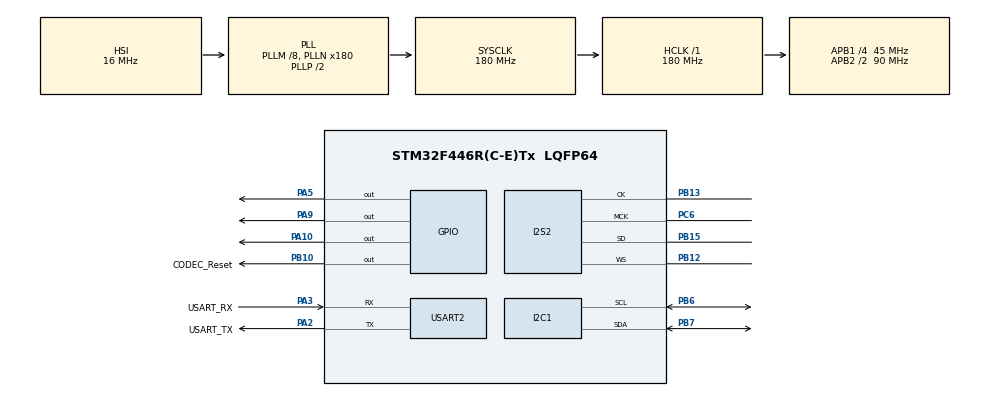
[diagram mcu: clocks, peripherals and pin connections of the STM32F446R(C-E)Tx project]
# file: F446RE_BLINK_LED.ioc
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I2S2.ErrorAudioFreq=1.72 %
I2S2.FullDuplexMode=I2S_FULLDUPLEXMODE_DISABLE
I2S2.Instance=SPI$Index
I2S2.RealAudioFreq=8.138 KHz
I2S2.VirtualMode=I2S_MODE_MASTER
Mcu.Family=STM32F4
Mcu.Name=STM32F446R(C-E)Tx
Mcu.Package=LQFP64
NVIC.PriorityGroup=NVIC_PRIORITYGROUP_0
PA10.Signal=GPIO_Output
PA13.GPIO_Label=TMS
PA13.Mode=Serial_Wire
PA13.Signal=SYS_JTMS-SWDIO
PA14.GPIO_Label=TCK
PA14.Mode=Serial_Wire
PA14.Signal=SYS_JTCK-SWCLK
PA2.GPIO_Label=USART_TX
PA2.Mode=Asynchronous
PA2.Signal=USART2_TX
PA3.GPIO_Label=USART_RX
PA3.Mode=Asynchronous
PA3.Signal=USART2_RX
PA5.Signal=GPIO_Output
PA9.Signal=GPIO_Output
PB10.GPIO_Label=CODEC_Reset
PB10.Signal=GPIO_Output
PB12.Mode=Half_Duplex_Master
PB12.Signal=I2S2_WS
PB13.Mode=Half_Duplex_Master
PB13.Signal=I2S2_CK
PB15.Mode=Half_Duplex_Master
PB15.Signal=I2S2_SD
PB6.Mode=I2C
PB6.Signal=I2C1_SCL
PB7.Mode=I2C
PB7.Signal=I2C1_SDA
PC6.Mode=Master_Clock_Activated
PC6.Signal=I2S2_MCK
PH0-OSC_IN.Mode=HSE-External-Oscillator
PH0-OSC_IN.Signal=RCC_OSC_IN
PH1-OSC_OUT.Mode=HSE-External-Oscillator
PH1-OSC_OUT.Signal=RCC_OSC_OUT
ProjectManager.HeapSize=0x200
ProjectManager.StackSize=0x400
ProjectManager.TargetToolchain=STM32CubeIDE
RCC.48MHZClocksFreq_Value=84000000
RCC.AHBFreq_Value=180000000
RCC.APB1CLKDivider=RCC_HCLK_DIV4
RCC.APB1Freq_Value=45000000
RCC.APB1TimFreq_Value=90000000
RCC.APB2CLKDivider=RCC_HCLK_DIV2
RCC.APB2Freq_Value=90000000
RCC.APB2TimFreq_Value=180000000
RCC.CortexFreq_Value=180000000
RCC.FLatency-AdvancedSettings=FLASH_LATENCY_5
RCC.HCLKFreq_Value=180000000
RCC.HSE_Timout=100
RCC.HSE_VALUE=16000000
RCC.HSI_VALUE=16000000
RCC.PLLI2SM=8
RCC.PLLI2SN=50
RCC.PLLM=8
RCC.PLLN=180
RCC.SYSCLKFreq_VALUE=180000000
RCC.SYSCLKSource=RCC_SYSCLKSOURCE_PLLCLK
RCC.USBFreq_Value=180000000
RCC.VCOOutputFreq_Value=360000000
USART2.VirtualMode=VM_ASYNC
VP_CRC_VS_CRC.Mode=CRC_Activate
board=NUCLEO-F446RE

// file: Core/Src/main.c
/* USER CODE BEGIN Header */
/**
  ******************************************************************************
  * @file           : main.c
  * @brief          : Main program body
  ******************************************************************************
  * @attention
  *
  * Copyright (c) 2022 STMicroelectronics.
  * All rights reserved.
  *
  * This software is licensed under terms that can be found in the LICENSE file
  * in the root directory of this software component.
  * If no LICENSE file comes with this software, it is provided AS-IS.
  *
  ******************************************************************************
  */
/* USER CODE END Header */
#include "main.h"

CRC_HandleTypeDef hcrc;

I2C_HandleTypeDef hi2c1;

I2S_HandleTypeDef hi2s2;

UART_HandleTypeDef huart2;

void SystemClock_Config(void);
static void MX_GPIO_Init(void);
static void MX_CRC_Init(void);
static void MX_USART2_UART_Init(void);
static void MX_I2C1_Init(void);
static void MX_I2S2_Init(void);

int main(void)
{

  /* MCU Configuration--------------------------------------------------------*/

  /* Reset of all peripherals, Initializes the Flash interface and the Systick. */
  HAL_Init();

  /* Configure the system clock */
  SystemClock_Config();

  /* Initialize all configured peripherals */
  MX_GPIO_Init();
  MX_CRC_Init();
  MX_USART2_UART_Init();
  MX_I2C1_Init();
  MX_I2S2_Init();

  /* Infinite loop */
  /* USER CODE BEGIN WHILE */
  while (1)
  {
	HAL_GPIO_TogglePin(GPIOA, GPIO_PIN_10);
	HAL_Delay(500);
	HAL_GPIO_TogglePin(GPIOA, GPIO_PIN_9);
	HAL_Delay(500);
    /* USER CODE END WHILE */

  }
}

void SystemClock_Config(void)
{
  RCC_OscInitTypeDef RCC_OscInitStruct = {0};
  RCC_ClkInitTypeDef RCC_ClkInitStruct = {0};

  /** Configure the main internal regulator output voltage
  */
  __HAL_RCC_PWR_CLK_ENABLE();
  __HAL_PWR_VOLTAGESCALING_CONFIG(PWR_REGULATOR_VOLTAGE_SCALE1);

  /** Initializes the RCC Oscillators according to the specified parameters
  * in the RCC_OscInitTypeDef structure.
  */
  RCC_OscInitStruct.OscillatorType = RCC_OSCILLATORTYPE_HSI;
  RCC_OscInitStruct.HSIState = RCC_HSI_ON;
  RCC_OscInitStruct.HSICalibrationValue = RCC_HSICALIBRATION_DEFAULT;
  RCC_OscInitStruct.PLL.PLLState = RCC_PLL_ON;
  RCC_OscInitStruct.PLL.PLLSource = RCC_PLLSOURCE_HSI;
  RCC_OscInitStruct.PLL.PLLM = 8;
  RCC_OscInitStruct.PLL.PLLN = 180;
  RCC_OscInitStruct.PLL.PLLP = RCC_PLLP_DIV2;
  RCC_OscInitStruct.PLL.PLLQ = 2;
  RCC_OscInitStruct.PLL.PLLR = 2;
  if (HAL_RCC_OscConfig(&RCC_OscInitStruct) != HAL_OK)
  {
    Error_Handler();
  }

  /** Activate the Over-Drive mode
  */
  if (HAL_PWREx_EnableOverDrive() != HAL_OK)
  {
    Error_Handler();
  }

  /** Initializes the CPU, AHB and APB buses clocks
  */
  RCC_ClkInitStruct.ClockType = RCC_CLOCKTYPE_HCLK|RCC_CLOCKTYPE_SYSCLK
                              |RCC_CLOCKTYPE_PCLK1|RCC_CLOCKTYPE_PCLK2;
  RCC_ClkInitStruct.SYSCLKSource = RCC_SYSCLKSOURCE_PLLCLK;
  RCC_ClkInitStruct.AHBCLKDivider = RCC_SYSCLK_DIV1;
  RCC_ClkInitStruct.APB1CLKDivider = RCC_HCLK_DIV4;
  RCC_ClkInitStruct.APB2CLKDivider = RCC_HCLK_DIV2;

  if (HAL_RCC_ClockConfig(&RCC_ClkInitStruct, FLASH_LATENCY_5) != HAL_OK)
  {
    Error_Handler();
  }
}

static void MX_CRC_Init(void)
{

  hcrc.Instance = CRC;
  if (HAL_CRC_Init(&hcrc) != HAL_OK)
  {
    Error_Handler();
  }

}

static void MX_I2C1_Init(void)
{

  hi2c1.Instance = I2C1;
  hi2c1.Init.ClockSpeed = 100000;
  hi2c1.Init.DutyCycle = I2C_DUTYCYCLE_2;
  hi2c1.Init.OwnAddress1 = 0;
  hi2c1.Init.AddressingMode = I2C_ADDRESSINGMODE_7BIT;
  hi2c1.Init.DualAddressMode = I2C_DUALADDRESS_DISABLE;
  hi2c1.Init.OwnAddress2 = 0;
  hi2c1.Init.GeneralCallMode = I2C_GENERALCALL_DISABLE;
  hi2c1.Init.NoStretchMode = I2C_NOSTRETCH_DISABLE;
  if (HAL_I2C_Init(&hi2c1) != HAL_OK)
  {
    Error_Handler();
  }

}

static void MX_I2S2_Init(void)
{

  hi2s2.Instance = SPI2;
  hi2s2.Init.Mode = I2S_MODE_MASTER_TX;
  hi2s2.Init.Standard = I2S_STANDARD_PHILIPS;
  hi2s2.Init.DataFormat = I2S_DATAFORMAT_16B;
  hi2s2.Init.MCLKOutput = I2S_MCLKOUTPUT_ENABLE;
  hi2s2.Init.AudioFreq = I2S_AUDIOFREQ_8K;
  hi2s2.Init.CPOL = I2S_CPOL_LOW;
  hi2s2.Init.ClockSource = I2S_CLOCK_PLL;
  hi2s2.Init.FullDuplexMode = I2S_FULLDUPLEXMODE_DISABLE;
  if (HAL_I2S_Init(&hi2s2) != HAL_OK)
  {
    Error_Handler();
  }

}

static void MX_USART2_UART_Init(void)
{

  huart2.Instance = USART2;
  huart2.Init.BaudRate = 115200;
  huart2.Init.WordLength = UART_WORDLENGTH_8B;
  huart2.Init.StopBits = UART_STOPBITS_1;
  huart2.Init.Parity = UART_PARITY_NONE;
  huart2.Init.Mode = UART_MODE_TX_RX;
  huart2.Init.HwFlowCtl = UART_HWCONTROL_NONE;
  huart2.Init.OverSampling = UART_OVERSAMPLING_16;
  if (HAL_UART_Init(&huart2) != HAL_OK)
  {
    Error_Handler();
  }

}

static void MX_GPIO_Init(void)
{
  GPIO_InitTypeDef GPIO_InitStruct = {0};

  /* GPIO Ports Clock Enable */
  __HAL_RCC_GPIOH_CLK_ENABLE();
  __HAL_RCC_GPIOA_CLK_ENABLE();
  __HAL_RCC_GPIOB_CLK_ENABLE();
  __HAL_RCC_GPIOC_CLK_ENABLE();

  /*Configure GPIO pin Output Level */
  HAL_GPIO_WritePin(GPIOA, GPIO_PIN_5|GPIO_PIN_9|GPIO_PIN_10, GPIO_PIN_RESET);

  /*Configure GPIO pin Output Level */
  HAL_GPIO_WritePin(CODEC_Reset_GPIO_Port, CODEC_Reset_Pin, GPIO_PIN_RESET);

  /*Configure GPIO pins : PA5 PA9 PA10 */
  GPIO_InitStruct.Pin = GPIO_PIN_5|GPIO_PIN_9|GPIO_PIN_10;
  GPIO_InitStruct.Mode = GPIO_MODE_OUTPUT_PP;
  GPIO_InitStruct.Pull = GPIO_NOPULL;
  GPIO_InitStruct.Speed = GPIO_SPEED_FREQ_LOW;
  HAL_GPIO_Init(GPIOA, &GPIO_InitStruct);

  /*Configure GPIO pin : CODEC_Reset_Pin */
  GPIO_InitStruct.Pin = CODEC_Reset_Pin;
  GPIO_InitStruct.Mode = GPIO_MODE_OUTPUT_PP;
  GPIO_InitStruct.Pull = GPIO_NOPULL;
  GPIO_InitStruct.Speed = GPIO_SPEED_FREQ_LOW;
  HAL_GPIO_Init(CODEC_Reset_GPIO_Port, &GPIO_InitStruct);

}

void Error_Handler(void)
{
  /* USER CODE BEGIN Error_Handler_Debug */
  /* User can add his own implementation to report the HAL error return state */
  __disable_irq();
  while (1)
  {
		HAL_GPIO_TogglePin(GPIOA, GPIO_PIN_10);
		HAL_Delay(500);

		HAL_GPIO_TogglePin(GPIOA, GPIO_PIN_9);
		HAL_Delay(500);
  }
  /* USER CODE END Error_Handler_Debug */
}
